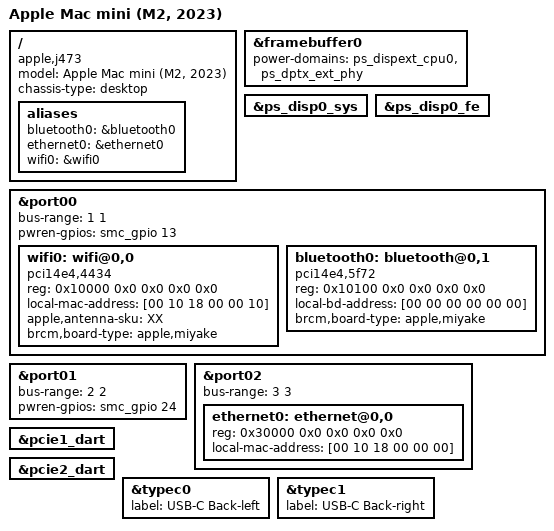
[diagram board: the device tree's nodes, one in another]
// SPDX-License-Identifier: GPL-2.0+ OR MIT
/*
 * Apple Mac mini (M2, 2023)
 *
 * target-type: J473
 *
 * Copyright The Asahi Linux Contributors
 */

/dts-v1/;

#include "t8112.dtsi"
#include "t8112-jxxx.dtsi"

/ {
	compatible = "apple,j473", "apple,t8112", "apple,arm-platform";
	model = "Apple Mac mini (M2, 2023)";
	chassis-type = "desktop";

	aliases {
		bluetooth0 = &bluetooth0;
		ethernet0 = &ethernet0;
		wifi0 = &wifi0;
	};
};

/*
 * Keep the power-domains used for the HDMI port on.
 */
&framebuffer0 {
	power-domains = <&ps_dispext_cpu0>, <&ps_dptx_ext_phy>;
};

/*
 * The M2 Mac mini uses dispext for the HDMI output so it's not necessary to
 * keep disp0 power-domains always-on.
 */
&ps_disp0_sys {
	/delete-property/ apple,always-on;
};

&ps_disp0_fe {
	/delete-property/ apple,always-on;
};

/*
 * Force the bus number assignments so that we can declare some of the
 * on-board devices and properties that are populated by the bootloader
 * (such as MAC addresses).
 */
&port00 {
	bus-range = <1 1>;
	pwren-gpios = <&smc_gpio 13 GPIO_ACTIVE_HIGH>;
	wifi0: wifi@0,0 {
		compatible = "pci14e4,4434";
		reg = <0x10000 0x0 0x0 0x0 0x0>;
		/* To be filled by the loader */
		local-mac-address = [00 10 18 00 00 10];
		apple,antenna-sku = "XX";
		brcm,board-type = "apple,miyake";
	};

	bluetooth0: bluetooth@0,1 {
		compatible = "pci14e4,5f72";
		reg = <0x10100 0x0 0x0 0x0 0x0>;
		/* To be filled by the loader */
		local-bd-address = [00 00 00 00 00 00];
		brcm,board-type = "apple,miyake";
	};
};

&port01 {
	bus-range = <2 2>;
	pwren-gpios = <&smc_gpio 24 GPIO_ACTIVE_HIGH>;
	status = "okay";
};

&port02 {
	bus-range = <3 3>;
	status = "okay";
	ethernet0: ethernet@0,0 {
		reg = <0x30000 0x0 0x0 0x0 0x0>;
		/* To be filled by the loader */
		local-mac-address = [00 10 18 00 00 00];
	};
};

&pcie1_dart {
	status = "okay";
};

&pcie2_dart {
	status = "okay";
};

/*
 * Provide labels for the USB type C ports.
 */

&typec0 {
	label = "USB-C Back-left";
};

&typec1 {
	label = "USB-C Back-right";
};

#include "hwmon-mini.dtsi"
